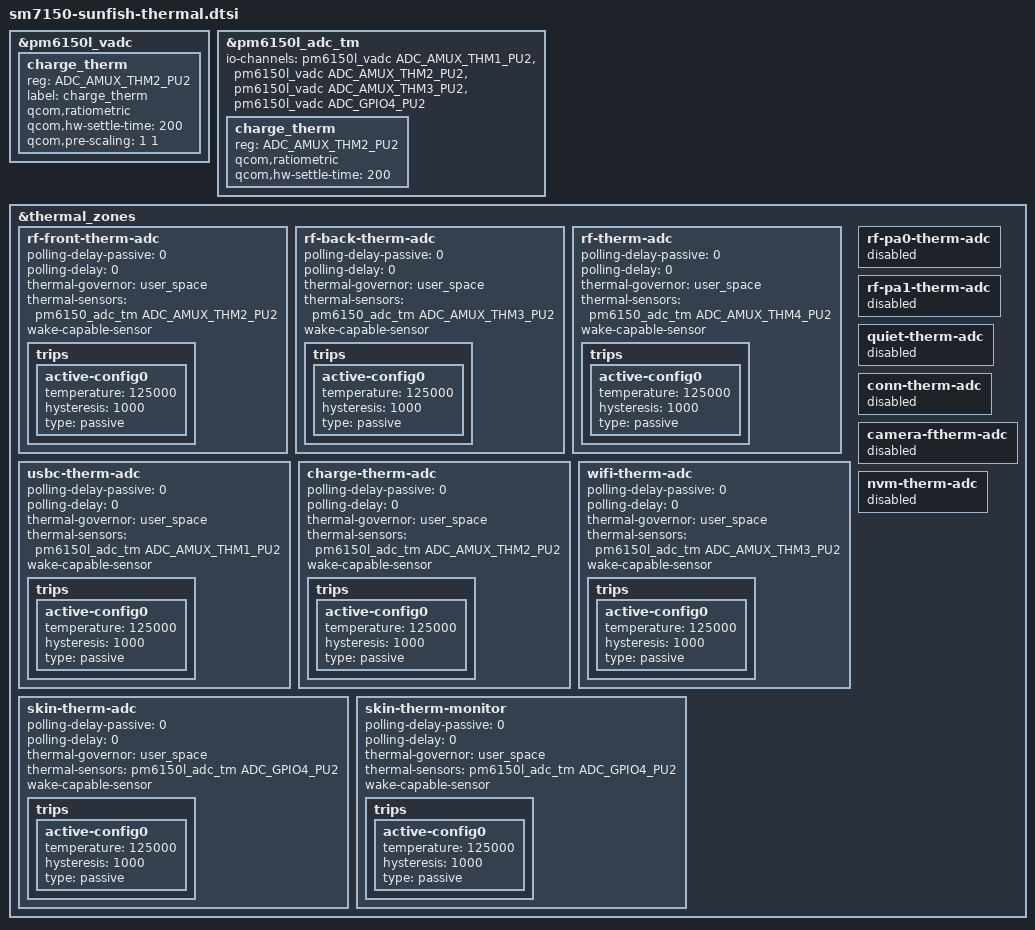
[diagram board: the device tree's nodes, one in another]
/* Copyright (c) 2018-2019, The Linux Foundation. All rights reserved.
 *
 * This program is free software; you can redistribute it and/or modify
 * it under the terms of the GNU General Public License version 2 and
 * only version 2 as published by the Free Software Foundation.
 *
 * This program is distributed in the hope that it will be useful,
 * but WITHOUT ANY WARRANTY; without even the implied warranty of
 * MERCHANTABILITY or FITNESS FOR A PARTICULAR PURPOSE.  See the
 * GNU General Public License for more details.
 */

&pm6150l_vadc {
	charge_therm {
		reg = <ADC_AMUX_THM2_PU2>;
		label = "charge_therm";
		qcom,ratiometric;
		qcom,hw-settle-time = <200>;
		qcom,pre-scaling = <1 1>;
	};
};

&pm6150l_adc_tm {
	io-channels = <&pm6150l_vadc ADC_AMUX_THM1_PU2>,
			<&pm6150l_vadc ADC_AMUX_THM2_PU2>,
			<&pm6150l_vadc ADC_AMUX_THM3_PU2>,
			<&pm6150l_vadc ADC_GPIO4_PU2>;

	charge_therm {
		reg = <ADC_AMUX_THM2_PU2>;
		qcom,ratiometric;
		qcom,hw-settle-time = <200>;
	};
};

/*
 * Vadc: pm6150_vadc
 * Rename rf-pa0-therm-adc to rf-front-therm-adc, label: rf_pa0_therm
 * Rename rf-pa1-therm-adc to rf-back-therm-adc, label: rf_pa1_therm
 * Rename quiet-therm-adc to rf-therm-adc, label: quiet_therm
 * Vadc: pm6150l_vadc
 * Rename conn-therm-adc to usbc-therm-adc, label: conn_therm
 * Rename camera-ftherm-adc to wifi-therm-adc, label: camera_ftherm
 * Rename nvm-therm-adc to skin-therm-adc, label: nvm_therm
 * Add charge-therm-adc, label: charge_therm
 */
&thermal_zones {
	rf-front-therm-adc {
		polling-delay-passive = <0>;
		polling-delay = <0>;
		thermal-governor = "user_space";
		thermal-sensors = <&pm6150_adc_tm ADC_AMUX_THM2_PU2>;
		wake-capable-sensor;
		trips {
			active-config0 {
				temperature = <125000>;
				hysteresis = <1000>;
				type = "passive";
			};
		};
	};

	rf-back-therm-adc {
		polling-delay-passive = <0>;
		polling-delay = <0>;
		thermal-governor = "user_space";
		thermal-sensors = <&pm6150_adc_tm ADC_AMUX_THM3_PU2>;
		wake-capable-sensor;
		trips {
			active-config0 {
				temperature = <125000>;
				hysteresis = <1000>;
				type = "passive";
			};
		};
	};

	rf-therm-adc {
		polling-delay-passive = <0>;
		polling-delay = <0>;
		thermal-governor = "user_space";
		thermal-sensors = <&pm6150_adc_tm ADC_AMUX_THM4_PU2>;
		wake-capable-sensor;
		trips {
			active-config0 {
				temperature = <125000>;
				hysteresis = <1000>;
				type = "passive";
			};
		};
	};

	usbc-therm-adc {
		polling-delay-passive = <0>;
		polling-delay = <0>;
		thermal-governor = "user_space";
		thermal-sensors = <&pm6150l_adc_tm ADC_AMUX_THM1_PU2>;
		wake-capable-sensor;
		trips {
			active-config0 {
				temperature = <125000>;
				hysteresis = <1000>;
				type = "passive";
			};
		};
	};

	charge-therm-adc {
		polling-delay-passive = <0>;
		polling-delay = <0>;
		thermal-governor = "user_space";
		thermal-sensors = <&pm6150l_adc_tm ADC_AMUX_THM2_PU2>;
		wake-capable-sensor;
		trips {
			active-config0 {
				temperature = <125000>;
				hysteresis = <1000>;
				type = "passive";
			};
		};
	};

	wifi-therm-adc {
		polling-delay-passive = <0>;
		polling-delay = <0>;
		thermal-governor = "user_space";
		thermal-sensors = <&pm6150l_adc_tm ADC_AMUX_THM3_PU2>;
		wake-capable-sensor;
		trips {
			active-config0 {
				temperature = <125000>;
				hysteresis = <1000>;
				type = "passive";
			};
		};
	};

	skin-therm-adc {
		polling-delay-passive = <0>;
		polling-delay = <0>;
		thermal-governor = "user_space";
		thermal-sensors = <&pm6150l_adc_tm ADC_GPIO4_PU2>;
		wake-capable-sensor;
		trips {
			active-config0 {
				temperature = <125000>;
				hysteresis = <1000>;
				type = "passive";
			};
		};
	};

	skin-therm-monitor {
		polling-delay-passive = <0>;
		polling-delay = <0>;
		thermal-governor = "user_space";
		thermal-sensors = <&pm6150l_adc_tm ADC_GPIO4_PU2>;
		wake-capable-sensor;
		trips {
			active-config0 {
				temperature = <125000>;
				hysteresis = <1000>;
				type = "passive";
			};
		};
	};

	rf-pa0-therm-adc {
		status = "disabled";
	};

	rf-pa1-therm-adc {
		status = "disabled";
	};

	quiet-therm-adc {
		status = "disabled";
	};

	conn-therm-adc {
		status = "disabled";
	};

	camera-ftherm-adc {
		status = "disabled";
	};

	nvm-therm-adc {
		status = "disabled";
	};
};
